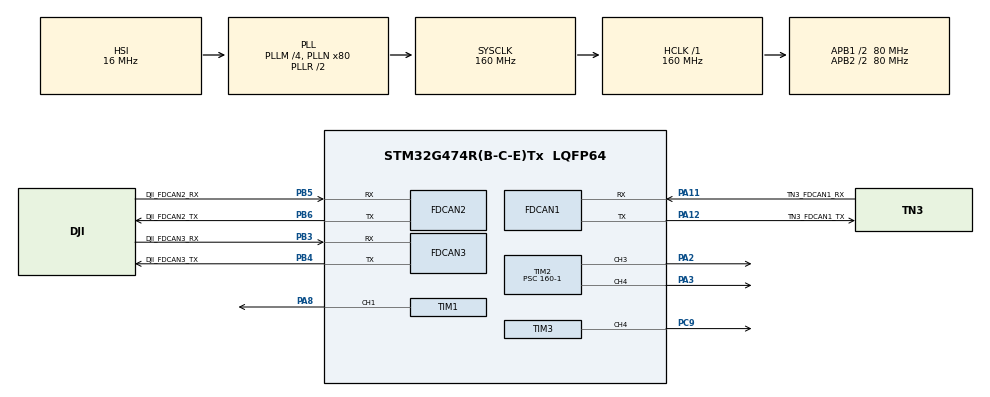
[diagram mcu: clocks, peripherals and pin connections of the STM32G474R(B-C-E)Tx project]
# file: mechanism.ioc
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Dma.Request0=TIM1_CH1
Dma.TIM1_CH1.0.Direction=DMA_MEMORY_TO_PERIPH
Dma.TIM1_CH1.0.EventEnable=DISABLE
Dma.TIM1_CH1.0.Instance=DMA1_Channel2
Dma.TIM1_CH1.0.MemDataAlignment=DMA_MDATAALIGN_WORD
Dma.TIM1_CH1.0.MemInc=DMA_MINC_ENABLE
Dma.TIM1_CH1.0.Mode=DMA_NORMAL
Dma.TIM1_CH1.0.PeriphDataAlignment=DMA_PDATAALIGN_WORD
Dma.TIM1_CH1.0.PeriphInc=DMA_PINC_DISABLE
Dma.TIM1_CH1.0.Polarity=HAL_DMAMUX_REQ_GEN_RISING
Dma.TIM1_CH1.0.Priority=DMA_PRIORITY_VERY_HIGH
Dma.TIM1_CH1.0.RequestNumber=1
Dma.TIM1_CH1.0.SignalID=NONE
Dma.TIM1_CH1.0.SyncEnable=DISABLE
Dma.TIM1_CH1.0.SyncPolarity=HAL_DMAMUX_SYNC_NO_EVENT
Dma.TIM1_CH1.0.SyncRequestNumber=1
Dma.TIM1_CH1.0.SyncSignalID=NONE
FDCAN1.CalculateBaudRateNominal=1000000
FDCAN1.CalculateTimeBitNominal=1000
FDCAN1.CalculateTimeQuantumNominal=12.5
FDCAN1.DataSyncJumpWidth=3
FDCAN1.DataTimeSeg1=12
FDCAN1.DataTimeSeg2=3
FDCAN1.FrameFormat=FDCAN_FRAME_FD_BRS
FDCAN1.NominalPrescaler=1
FDCAN1.NominalSyncJumpWidth=15
FDCAN1.NominalTimeSeg1=64
FDCAN1.NominalTimeSeg2=15
FDCAN1.StdFiltersNbr=1
FDCAN2.CalculateBaudRateNominal=1000000
FDCAN2.CalculateTimeBitNominal=1000
FDCAN2.CalculateTimeQuantumNominal=12.5
FDCAN2.DataSyncJumpWidth=3
FDCAN2.DataTimeSeg1=12
FDCAN2.DataTimeSeg2=3
FDCAN2.NominalPrescaler=1
FDCAN2.NominalSyncJumpWidth=15
FDCAN2.NominalTimeSeg1=64
FDCAN2.NominalTimeSeg2=15
FDCAN2.StdFiltersNbr=1
FDCAN3.CalculateBaudRateNominal=1000000
FDCAN3.CalculateTimeBitNominal=1000
FDCAN3.CalculateTimeQuantumNominal=12.5
FDCAN3.DataSyncJumpWidth=3
FDCAN3.DataTimeSeg1=12
FDCAN3.DataTimeSeg2=3
FDCAN3.ExtFiltersNbr=0
FDCAN3.NominalPrescaler=1
FDCAN3.NominalSyncJumpWidth=15
FDCAN3.NominalTimeSeg1=64
FDCAN3.NominalTimeSeg2=15
FDCAN3.StdFiltersNbr=1
Mcu.Family=STM32G4
Mcu.Name=STM32G474R(B-C-E)Tx
Mcu.Package=LQFP64
NVIC.DMA1_Channel2_IRQn=true\:0\:0\:false\:false\:true\:false\:true\:true
NVIC.FDCAN1_IT0_IRQn=true\:14\:0\:true\:false\:true\:true\:true\:true
NVIC.FDCAN2_IT0_IRQn=true\:15\:0\:true\:false\:true\:true\:true\:true
NVIC.FDCAN3_IT0_IRQn=true\:13\:0\:true\:false\:true\:true\:true\:true
NVIC.PriorityGroup=NVIC_PRIORITYGROUP_4
NVIC.TIM6_DAC_IRQn=true\:0\:0\:false\:false\:true\:true\:true\:true
PA11.GPIO_Label=TN3_FDCAN1_RX
PA11.GPIO_Speed=GPIO_SPEED_FREQ_VERY_HIGH
PA11.Mode=FDCAN_Activate
PA11.Signal=FDCAN1_RX
PA12.GPIO_Label=TN3_FDCAN1_TX
PA12.GPIO_Speed=GPIO_SPEED_FREQ_VERY_HIGH
PA12.Mode=FDCAN_Activate
PA12.Signal=FDCAN1_TX
PA13.Mode=Serial_Wire
PA13.Signal=SYS_JTMS-SWDIO
PA14.Mode=Serial_Wire
PA14.Signal=SYS_JTCK-SWCLK
PA2.Signal=S_TIM2_CH3
PA3.Signal=S_TIM2_CH4
PA8.Signal=S_TIM1_CH1
PB3.GPIO_Label=DJI_FDCAN3_RX
PB3.GPIO_Speed=GPIO_SPEED_FREQ_VERY_HIGH
PB3.Mode=FDCAN_Activate
PB3.Signal=FDCAN3_RX
PB4.GPIO_Label=DJI_FDCAN3_TX
PB4.GPIO_Speed=GPIO_SPEED_FREQ_VERY_HIGH
PB4.Mode=FDCAN_Activate
PB4.Signal=FDCAN3_TX
PB5.GPIO_Label=DJI_FDCAN2_RX
PB5.GPIO_Speed=GPIO_SPEED_FREQ_VERY_HIGH
PB5.Mode=FDCAN_Activate
PB5.Signal=FDCAN2_RX
PB6.GPIO_FM6=__NULL
PB6.GPIO_Label=DJI_FDCAN2_TX
PB6.GPIO_Speed=GPIO_SPEED_FREQ_VERY_HIGH
PB6.Mode=FDCAN_Activate
PB6.Signal=FDCAN2_TX
PC9.Signal=S_TIM3_CH4
ProjectManager.HeapSize=0x200
ProjectManager.StackSize=0x400
ProjectManager.TargetToolchain=STM32CubeIDE
RCC.ADC12Freq_Value=160000000
RCC.ADC345Freq_Value=160000000
RCC.AHBFreq_Value=160000000
RCC.APB1CLKDivider=RCC_HCLK_DIV2
RCC.APB1Freq_Value=80000000
RCC.APB1TimFreq_Value=160000000
RCC.APB2CLKDivider=RCC_HCLK_DIV2
RCC.APB2Freq_Value=80000000
RCC.APB2TimFreq_Value=160000000
RCC.CortexFreq_Value=160000000
RCC.EXTERNAL_CLOCK_VALUE=12288000
RCC.HCLKFreq_Value=160000000
RCC.HSE_VALUE=8000000
RCC.HSI48_VALUE=48000000
RCC.HSI_VALUE=16000000
RCC.LSE_VALUE=32768
RCC.PLLM=RCC_PLLM_DIV4
RCC.PLLN=80
RCC.PLLQ=RCC_PLLQ_DIV4
RCC.SYSCLKFreq_VALUE=160000000
RCC.SYSCLKSource=RCC_SYSCLKSOURCE_PLLCLK
RCC.USBFreq_Value=80000000
RCC.VCOOutputFreq_Value=320000000
SH.S_TIM1_CH1.0=TIM1_CH1,PWM Generation1 CH1
SH.S_TIM2_CH3.0=TIM2_CH3,PWM Generation3 CH3
SH.S_TIM2_CH4.0=TIM2_CH4,PWM Generation4 CH4
SH.S_TIM3_CH4.0=TIM3_CH4,PWM Generation4 CH4
TIM1.Channel-PWM\ Generation1\ CH1=TIM_CHANNEL_1
TIM1.PeriodNoDither=25-1
TIM1.Prescaler=8-1
TIM2.Channel-PWM\ Generation3\ CH3=TIM_CHANNEL_3
TIM2.Channel-PWM\ Generation4\ CH4=TIM_CHANNEL_4
TIM2.PeriodNoDither=20000-1
TIM2.Prescaler=160-1
TIM3.Channel-PWM\ Generation4\ CH4=TIM_CHANNEL_4
TIM3.PeriodNoDither=20000-1
TIM3.Prescaler=160-1
TIM5.Prescaler=160-1
TIM6.PeriodNoDither=1000-1
TIM6.Prescaler=160-1
TIM7.Prescaler=160-1
VP_SYS_VS_DBSignals.Mode=DisableDeadBatterySignals
VP_TIM1_VS_ClockSourceINT.Mode=Internal
VP_TIM2_VS_ClockSourceINT.Mode=Internal
VP_TIM3_VS_ClockSourceINT.Mode=Internal
VP_TIM5_VS_ClockSourceINT.Mode=Internal
VP_TIM6_VS_ClockSourceINT.Mode=Enable_Timer
VP_TIM7_VS_ClockSourceINT.Mode=Enable_Timer
board=custom

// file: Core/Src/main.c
/* USER CODE BEGIN Header */
/**
  ******************************************************************************
  * @file           : main.c
  * @brief          : Main program body
  ******************************************************************************
  * @attention
  *
  * Copyright (c) 2024 STMicroelectronics.
  * All rights reserved.
  *
  * This software is licensed under terms that can be found in the LICENSE file
  * in the root directory of this software component.
  * If no LICENSE file comes with this software, it is provided AS-IS.
  *
  ******************************************************************************
  */
/* USER CODE END Header */
#include "main.h"

/* USER CODE BEGIN Includes */
#include "code.hpp"
/* USER CODE END Includes */

FDCAN_HandleTypeDef hfdcan1;
FDCAN_HandleTypeDef hfdcan2;
FDCAN_HandleTypeDef hfdcan3;

TIM_HandleTypeDef htim1;
TIM_HandleTypeDef htim2;
TIM_HandleTypeDef htim3;
TIM_HandleTypeDef htim5;
TIM_HandleTypeDef htim6;
TIM_HandleTypeDef htim7;
DMA_HandleTypeDef hdma_tim1_ch1;

void SystemClock_Config(void);
static void MX_GPIO_Init(void);
static void MX_DMA_Init(void);
static void MX_FDCAN1_Init(void);
static void MX_FDCAN3_Init(void);
static void MX_TIM6_Init(void);
static void MX_TIM7_Init(void);
static void MX_FDCAN2_Init(void);
static void MX_TIM5_Init(void);
static void MX_TIM2_Init(void);
static void MX_TIM3_Init(void);
static void MX_TIM1_Init(void);

int main(void)
{

  /* MCU Configuration--------------------------------------------------------*/

  /* Reset of all peripherals, Initializes the Flash interface and the Systick. */
  HAL_Init();

  /* Configure the system clock */
  SystemClock_Config();

  /* Initialize all configured peripherals */
  MX_GPIO_Init();
  MX_DMA_Init();
  MX_FDCAN1_Init();
  MX_FDCAN3_Init();
  MX_TIM6_Init();
  MX_TIM7_Init();
  MX_FDCAN2_Init();
  MX_TIM5_Init();
  MX_TIM2_Init();
  MX_TIM3_Init();
  MX_TIM1_Init();
  /* USER CODE BEGIN 2 */
  setup();
  /* USER CODE END 2 */

  /* Infinite loop */
  while (1)
  {

    /* USER CODE BEGIN 3 */
    loop();
  }
  /* USER CODE END 3 */
}

void SystemClock_Config(void)
{
  RCC_OscInitTypeDef RCC_OscInitStruct = {0};
  RCC_ClkInitTypeDef RCC_ClkInitStruct = {0};

  /** Configure the main internal regulator output voltage
  */
  HAL_PWREx_ControlVoltageScaling(PWR_REGULATOR_VOLTAGE_SCALE1_BOOST);

  /** Initializes the RCC Oscillators according to the specified parameters
  * in the RCC_OscInitTypeDef structure.
  */
  RCC_OscInitStruct.OscillatorType = RCC_OSCILLATORTYPE_HSI;
  RCC_OscInitStruct.HSIState = RCC_HSI_ON;
  RCC_OscInitStruct.HSICalibrationValue = RCC_HSICALIBRATION_DEFAULT;
  RCC_OscInitStruct.PLL.PLLState = RCC_PLL_ON;
  RCC_OscInitStruct.PLL.PLLSource = RCC_PLLSOURCE_HSI;
  RCC_OscInitStruct.PLL.PLLM = RCC_PLLM_DIV4;
  RCC_OscInitStruct.PLL.PLLN = 80;
  RCC_OscInitStruct.PLL.PLLP = RCC_PLLP_DIV2;
  RCC_OscInitStruct.PLL.PLLQ = RCC_PLLQ_DIV4;
  RCC_OscInitStruct.PLL.PLLR = RCC_PLLR_DIV2;
  if (HAL_RCC_OscConfig(&RCC_OscInitStruct) != HAL_OK)
  {
    Error_Handler();
  }

  /** Initializes the CPU, AHB and APB buses clocks
  */
  RCC_ClkInitStruct.ClockType = RCC_CLOCKTYPE_HCLK|RCC_CLOCKTYPE_SYSCLK
                              |RCC_CLOCKTYPE_PCLK1|RCC_CLOCKTYPE_PCLK2;
  RCC_ClkInitStruct.SYSCLKSource = RCC_SYSCLKSOURCE_PLLCLK;
  RCC_ClkInitStruct.AHBCLKDivider = RCC_SYSCLK_DIV1;
  RCC_ClkInitStruct.APB1CLKDivider = RCC_HCLK_DIV2;
  RCC_ClkInitStruct.APB2CLKDivider = RCC_HCLK_DIV2;

  if (HAL_RCC_ClockConfig(&RCC_ClkInitStruct, FLASH_LATENCY_4) != HAL_OK)
  {
    Error_Handler();
  }
}

static void MX_FDCAN1_Init(void)
{

  hfdcan1.Instance = FDCAN1;
  hfdcan1.Init.ClockDivider = FDCAN_CLOCK_DIV1;
  hfdcan1.Init.FrameFormat = FDCAN_FRAME_FD_BRS;
  hfdcan1.Init.Mode = FDCAN_MODE_NORMAL;
  hfdcan1.Init.AutoRetransmission = DISABLE;
  hfdcan1.Init.TransmitPause = DISABLE;
  hfdcan1.Init.ProtocolException = DISABLE;
  hfdcan1.Init.NominalPrescaler = 1;
  hfdcan1.Init.NominalSyncJumpWidth = 15;
  hfdcan1.Init.NominalTimeSeg1 = 64;
  hfdcan1.Init.NominalTimeSeg2 = 15;
  hfdcan1.Init.DataPrescaler = 1;
  hfdcan1.Init.DataSyncJumpWidth = 3;
  hfdcan1.Init.DataTimeSeg1 = 12;
  hfdcan1.Init.DataTimeSeg2 = 3;
  hfdcan1.Init.StdFiltersNbr = 1;
  hfdcan1.Init.ExtFiltersNbr = 0;
  hfdcan1.Init.TxFifoQueueMode = FDCAN_TX_FIFO_OPERATION;
  if (HAL_FDCAN_Init(&hfdcan1) != HAL_OK)
  {
    Error_Handler();
  }

}

static void MX_FDCAN2_Init(void)
{

  hfdcan2.Instance = FDCAN2;
  hfdcan2.Init.ClockDivider = FDCAN_CLOCK_DIV1;
  hfdcan2.Init.FrameFormat = FDCAN_FRAME_CLASSIC;
  hfdcan2.Init.Mode = FDCAN_MODE_NORMAL;
  hfdcan2.Init.AutoRetransmission = DISABLE;
  hfdcan2.Init.TransmitPause = DISABLE;
  hfdcan2.Init.ProtocolException = DISABLE;
  hfdcan2.Init.NominalPrescaler = 1;
  hfdcan2.Init.NominalSyncJumpWidth = 15;
  hfdcan2.Init.NominalTimeSeg1 = 64;
  hfdcan2.Init.NominalTimeSeg2 = 15;
  hfdcan2.Init.DataPrescaler = 1;
  hfdcan2.Init.DataSyncJumpWidth = 3;
  hfdcan2.Init.DataTimeSeg1 = 12;
  hfdcan2.Init.DataTimeSeg2 = 3;
  hfdcan2.Init.StdFiltersNbr = 1;
  hfdcan2.Init.ExtFiltersNbr = 0;
  hfdcan2.Init.TxFifoQueueMode = FDCAN_TX_FIFO_OPERATION;
  if (HAL_FDCAN_Init(&hfdcan2) != HAL_OK)
  {
    Error_Handler();
  }

}

static void MX_FDCAN3_Init(void)
{

  hfdcan3.Instance = FDCAN3;
  hfdcan3.Init.ClockDivider = FDCAN_CLOCK_DIV1;
  hfdcan3.Init.FrameFormat = FDCAN_FRAME_CLASSIC;
  hfdcan3.Init.Mode = FDCAN_MODE_NORMAL;
  hfdcan3.Init.AutoRetransmission = DISABLE;
  hfdcan3.Init.TransmitPause = DISABLE;
  hfdcan3.Init.ProtocolException = DISABLE;
  hfdcan3.Init.NominalPrescaler = 1;
  hfdcan3.Init.NominalSyncJumpWidth = 15;
  hfdcan3.Init.NominalTimeSeg1 = 64;
  hfdcan3.Init.NominalTimeSeg2 = 15;
  hfdcan3.Init.DataPrescaler = 1;
  hfdcan3.Init.DataSyncJumpWidth = 3;
  hfdcan3.Init.DataTimeSeg1 = 12;
  hfdcan3.Init.DataTimeSeg2 = 3;
  hfdcan3.Init.StdFiltersNbr = 1;
  hfdcan3.Init.ExtFiltersNbr = 0;
  hfdcan3.Init.TxFifoQueueMode = FDCAN_TX_FIFO_OPERATION;
  if (HAL_FDCAN_Init(&hfdcan3) != HAL_OK)
  {
    Error_Handler();
  }

}

static void MX_TIM1_Init(void)
{

  TIM_ClockConfigTypeDef sClockSourceConfig = {0};
  TIM_MasterConfigTypeDef sMasterConfig = {0};
  TIM_OC_InitTypeDef sConfigOC = {0};
  TIM_BreakDeadTimeConfigTypeDef sBreakDeadTimeConfig = {0};

  htim1.Instance = TIM1;
  htim1.Init.Prescaler = 8-1;
  htim1.Init.CounterMode = TIM_COUNTERMODE_UP;
  htim1.Init.Period = 24;
  htim1.Init.ClockDivision = TIM_CLOCKDIVISION_DIV1;
  htim1.Init.RepetitionCounter = 0;
  htim1.Init.AutoReloadPreload = TIM_AUTORELOAD_PRELOAD_DISABLE;
  if (HAL_TIM_Base_Init(&htim1) != HAL_OK)
  {
    Error_Handler();
  }
  sClockSourceConfig.ClockSource = TIM_CLOCKSOURCE_INTERNAL;
  if (HAL_TIM_ConfigClockSource(&htim1, &sClockSourceConfig) != HAL_OK)
  {
    Error_Handler();
  }
  if (HAL_TIM_PWM_Init(&htim1) != HAL_OK)
  {
    Error_Handler();
  }
  sMasterConfig.MasterOutputTrigger = TIM_TRGO_RESET;
  sMasterConfig.MasterOutputTrigger2 = TIM_TRGO2_RESET;
  sMasterConfig.MasterSlaveMode = TIM_MASTERSLAVEMODE_DISABLE;
  if (HAL_TIMEx_MasterConfigSynchronization(&htim1, &sMasterConfig) != HAL_OK)
  {
    Error_Handler();
  }
  sConfigOC.OCMode = TIM_OCMODE_PWM1;
  sConfigOC.Pulse = 0;
  sConfigOC.OCPolarity = TIM_OCPOLARITY_HIGH;
  sConfigOC.OCNPolarity = TIM_OCNPOLARITY_HIGH;
  sConfigOC.OCFastMode = TIM_OCFAST_DISABLE;
  sConfigOC.OCIdleState = TIM_OCIDLESTATE_RESET;
  sConfigOC.OCNIdleState = TIM_OCNIDLESTATE_RESET;
  if (HAL_TIM_PWM_ConfigChannel(&htim1, &sConfigOC, TIM_CHANNEL_1) != HAL_OK)
  {
    Error_Handler();
  }
  sBreakDeadTimeConfig.OffStateRunMode = TIM_OSSR_DISABLE;
  sBreakDeadTimeConfig.OffStateIDLEMode = TIM_OSSI_DISABLE;
  sBreakDeadTimeConfig.LockLevel = TIM_LOCKLEVEL_OFF;
  sBreakDeadTimeConfig.DeadTime = 0;
  sBreakDeadTimeConfig.BreakState = TIM_BREAK_DISABLE;
  sBreakDeadTimeConfig.BreakPolarity = TIM_BREAKPOLARITY_HIGH;
  sBreakDeadTimeConfig.BreakFilter = 0;
  sBreakDeadTimeConfig.BreakAFMode = TIM_BREAK_AFMODE_INPUT;
  sBreakDeadTimeConfig.Break2State = TIM_BREAK2_DISABLE;
  sBreakDeadTimeConfig.Break2Polarity = TIM_BREAK2POLARITY_HIGH;
  sBreakDeadTimeConfig.Break2Filter = 0;
  sBreakDeadTimeConfig.Break2AFMode = TIM_BREAK_AFMODE_INPUT;
  sBreakDeadTimeConfig.AutomaticOutput = TIM_AUTOMATICOUTPUT_DISABLE;
  if (HAL_TIMEx_ConfigBreakDeadTime(&htim1, &sBreakDeadTimeConfig) != HAL_OK)
  {
    Error_Handler();
  }
  HAL_TIM_MspPostInit(&htim1);

}

static void MX_TIM2_Init(void)
{

  TIM_ClockConfigTypeDef sClockSourceConfig = {0};
  TIM_MasterConfigTypeDef sMasterConfig = {0};
  TIM_OC_InitTypeDef sConfigOC = {0};

  htim2.Instance = TIM2;
  htim2.Init.Prescaler = 160-1;
  htim2.Init.CounterMode = TIM_COUNTERMODE_UP;
  htim2.Init.Period = 19999;
  htim2.Init.ClockDivision = TIM_CLOCKDIVISION_DIV1;
  htim2.Init.AutoReloadPreload = TIM_AUTORELOAD_PRELOAD_DISABLE;
  if (HAL_TIM_Base_Init(&htim2) != HAL_OK)
  {
    Error_Handler();
  }
  sClockSourceConfig.ClockSource = TIM_CLOCKSOURCE_INTERNAL;
  if (HAL_TIM_ConfigClockSource(&htim2, &sClockSourceConfig) != HAL_OK)
  {
    Error_Handler();
  }
  if (HAL_TIM_PWM_Init(&htim2) != HAL_OK)
  {
    Error_Handler();
  }
  sMasterConfig.MasterOutputTrigger = TIM_TRGO_RESET;
  sMasterConfig.MasterSlaveMode = TIM_MASTERSLAVEMODE_DISABLE;
  if (HAL_TIMEx_MasterConfigSynchronization(&htim2, &sMasterConfig) != HAL_OK)
  {
    Error_Handler();
  }
  sConfigOC.OCMode = TIM_OCMODE_PWM1;
  sConfigOC.Pulse = 0;
  sConfigOC.OCPolarity = TIM_OCPOLARITY_HIGH;
  sConfigOC.OCFastMode = TIM_OCFAST_DISABLE;
  if (HAL_TIM_PWM_ConfigChannel(&htim2, &sConfigOC, TIM_CHANNEL_3) != HAL_OK)
  {
    Error_Handler();
  }
  if (HAL_TIM_PWM_ConfigChannel(&htim2, &sConfigOC, TIM_CHANNEL_4) != HAL_OK)
  {
    Error_Handler();
  }
  HAL_TIM_MspPostInit(&htim2);

}

static void MX_TIM3_Init(void)
{

  TIM_ClockConfigTypeDef sClockSourceConfig = {0};
  TIM_MasterConfigTypeDef sMasterConfig = {0};
  TIM_OC_InitTypeDef sConfigOC = {0};

  htim3.Instance = TIM3;
  htim3.Init.Prescaler = 160-1;
  htim3.Init.CounterMode = TIM_COUNTERMODE_UP;
  htim3.Init.Period = 19999;
  htim3.Init.ClockDivision = TIM_CLOCKDIVISION_DIV1;
  htim3.Init.AutoReloadPreload = TIM_AUTORELOAD_PRELOAD_DISABLE;
  if (HAL_TIM_Base_Init(&htim3) != HAL_OK)
  {
    Error_Handler();
  }
  sClockSourceConfig.ClockSource = TIM_CLOCKSOURCE_INTERNAL;
  if (HAL_TIM_ConfigClockSource(&htim3, &sClockSourceConfig) != HAL_OK)
  {
    Error_Handler();
  }
  if (HAL_TIM_PWM_Init(&htim3) != HAL_OK)
  {
    Error_Handler();
  }
  sMasterConfig.MasterOutputTrigger = TIM_TRGO_RESET;
  sMasterConfig.MasterSlaveMode = TIM_MASTERSLAVEMODE_DISABLE;
  if (HAL_TIMEx_MasterConfigSynchronization(&htim3, &sMasterConfig) != HAL_OK)
  {
    Error_Handler();
  }
  sConfigOC.OCMode = TIM_OCMODE_PWM1;
  sConfigOC.Pulse = 0;
  sConfigOC.OCPolarity = TIM_OCPOLARITY_HIGH;
  sConfigOC.OCFastMode = TIM_OCFAST_DISABLE;
  if (HAL_TIM_PWM_ConfigChannel(&htim3, &sConfigOC, TIM_CHANNEL_4) != HAL_OK)
  {
    Error_Handler();
  }
  HAL_TIM_MspPostInit(&htim3);

}

static void MX_TIM5_Init(void)
{

  TIM_ClockConfigTypeDef sClockSourceConfig = {0};
  TIM_MasterConfigTypeDef sMasterConfig = {0};

  htim5.Instance = TIM5;
  htim5.Init.Prescaler = 160-1;
  htim5.Init.CounterMode = TIM_COUNTERMODE_UP;
  htim5.Init.Period = 4294967295;
  htim5.Init.ClockDivision = TIM_CLOCKDIVISION_DIV1;
  htim5.Init.AutoReloadPreload = TIM_AUTORELOAD_PRELOAD_DISABLE;
  if (HAL_TIM_Base_Init(&htim5) != HAL_OK)
  {
    Error_Handler();
  }
  sClockSourceConfig.ClockSource = TIM_CLOCKSOURCE_INTERNAL;
  if (HAL_TIM_ConfigClockSource(&htim5, &sClockSourceConfig) != HAL_OK)
  {
    Error_Handler();
  }
  sMasterConfig.MasterOutputTrigger = TIM_TRGO_RESET;
  sMasterConfig.MasterSlaveMode = TIM_MASTERSLAVEMODE_DISABLE;
  if (HAL_TIMEx_MasterConfigSynchronization(&htim5, &sMasterConfig) != HAL_OK)
  {
    Error_Handler();
  }

}

static void MX_TIM6_Init(void)
{

  TIM_MasterConfigTypeDef sMasterConfig = {0};

  htim6.Instance = TIM6;
  htim6.Init.Prescaler = 160-1;
  htim6.Init.CounterMode = TIM_COUNTERMODE_UP;
  htim6.Init.Period = 999;
  htim6.Init.AutoReloadPreload = TIM_AUTORELOAD_PRELOAD_DISABLE;
  if (HAL_TIM_Base_Init(&htim6) != HAL_OK)
  {
    Error_Handler();
  }
  sMasterConfig.MasterOutputTrigger = TIM_TRGO_RESET;
  sMasterConfig.MasterSlaveMode = TIM_MASTERSLAVEMODE_DISABLE;
  if (HAL_TIMEx_MasterConfigSynchronization(&htim6, &sMasterConfig) != HAL_OK)
  {
    Error_Handler();
  }

}

static void MX_TIM7_Init(void)
{

  TIM_MasterConfigTypeDef sMasterConfig = {0};

  htim7.Instance = TIM7;
  htim7.Init.Prescaler = 160-1;
  htim7.Init.CounterMode = TIM_COUNTERMODE_UP;
  htim7.Init.Period = 65535;
  htim7.Init.AutoReloadPreload = TIM_AUTORELOAD_PRELOAD_DISABLE;
  if (HAL_TIM_Base_Init(&htim7) != HAL_OK)
  {
    Error_Handler();
  }
  sMasterConfig.MasterOutputTrigger = TIM_TRGO_RESET;
  sMasterConfig.MasterSlaveMode = TIM_MASTERSLAVEMODE_DISABLE;
  if (HAL_TIMEx_MasterConfigSynchronization(&htim7, &sMasterConfig) != HAL_OK)
  {
    Error_Handler();
  }

}

static void MX_DMA_Init(void)
{

  /* DMA controller clock enable */
  __HAL_RCC_DMAMUX1_CLK_ENABLE();
  __HAL_RCC_DMA1_CLK_ENABLE();

  /* DMA interrupt init */
  /* DMA1_Channel2_IRQn interrupt configuration */
  HAL_NVIC_SetPriority(DMA1_Channel2_IRQn, 0, 0);
  HAL_NVIC_EnableIRQ(DMA1_Channel2_IRQn);

}

static void MX_GPIO_Init(void)
{

  /* GPIO Ports Clock Enable */
  __HAL_RCC_GPIOA_CLK_ENABLE();
  __HAL_RCC_GPIOC_CLK_ENABLE();
  __HAL_RCC_GPIOB_CLK_ENABLE();

}

void Error_Handler(void)
{
  __disable_irq();
  while (1)
  {
  }
}
